# STM32F207 register map
File version: 1.2
CPU: CM3 r1p1, little endian, no MPU, no FPU, 4 interrupt priority bits
Registers are 32-bit, read-write, reset 0x0 unless marked. A register's access mark holds for its fields unless they carry their own. Offsets are from the block's base; [hi:lo] are bit positions; {n}, {i} and the like mark numbered series.

## DCMI — Digital camera interface
Base 0x50050000
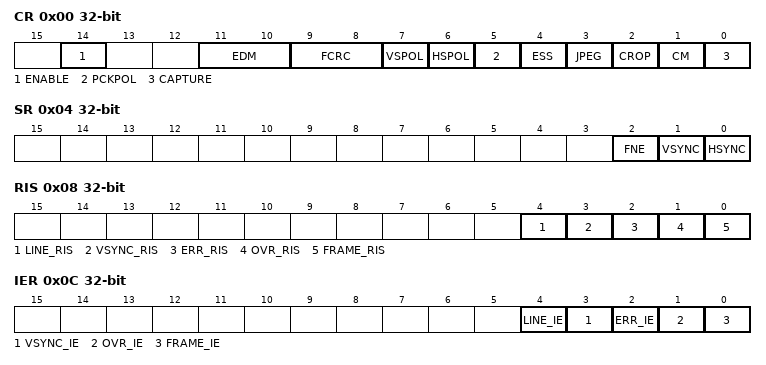
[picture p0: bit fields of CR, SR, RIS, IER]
0x00 CR — control register 1
  [14] ENABLE — DCMI enable
  [11:10] EDM — Extended data mode
  [9:8] FCRC — Frame capture rate control
  [7] VSPOL — Vertical synchronization polarity
  [6] HSPOL — Horizontal synchronization polarity
  [5] PCKPOL — Pixel clock polarity
  [4] ESS — Embedded synchronization select
  [3] JPEG — JPEG format
  [2] CROP — Crop feature
  [1] CM — Capture mode
  [0] CAPTURE — Capture enable
0x04 SR ro — status register
  [2] FNE — FIFO not empty
  [1] VSYNC
  [0] HSYNC
0x08 RIS ro — raw interrupt status register
  [4] LINE_RIS — Line raw interrupt status
  [3] VSYNC_RIS — VSYNC raw interrupt status
  [2] ERR_RIS — Synchronization error raw interrupt status
  [1] OVR_RIS — Overrun raw interrupt status
  [0] FRAME_RIS — Capture complete raw interrupt status
0x0C IER — interrupt enable register
  [4] LINE_IE — Line interrupt enable
  [3] VSYNC_IE — VSYNC interrupt enable
  [2] ERR_IE — Synchronization error interrupt enable
  [1] OVR_IE — Overrun interrupt enable
  [0] FRAME_IE — Capture complete interrupt enable
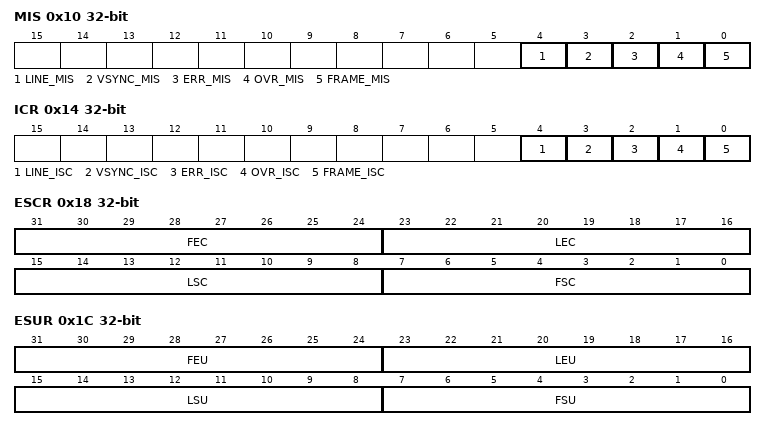
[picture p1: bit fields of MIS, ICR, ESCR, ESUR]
0x10 MIS ro — masked interrupt status register
  [4] LINE_MIS — Line masked interrupt status
  [3] VSYNC_MIS — VSYNC masked interrupt status
  [2] ERR_MIS — Synchronization error masked interrupt status
  [1] OVR_MIS — Overrun masked interrupt status
  [0] FRAME_MIS — Capture complete masked interrupt status
0x14 ICR wo — interrupt clear register
  [4] LINE_ISC — line interrupt status clear
  [3] VSYNC_ISC — Vertical synch interrupt status clear
  [2] ERR_ISC — Synchronization error interrupt status clear
  [1] OVR_ISC — Overrun interrupt status clear
  [0] FRAME_ISC — Capture complete interrupt status clear
0x18 ESCR — embedded synchronization code register
  [31:24] FEC — Frame end delimiter code
  [23:16] LEC — Line end delimiter code
  [15:8] LSC — Line start delimiter code
  [7:0] FSC — Frame start delimiter code
0x1C ESUR — embedded synchronization unmask register
  [31:24] FEU — Frame end delimiter unmask
  [23:16] LEU — Line end delimiter unmask
  [15:8] LSU — Line start delimiter unmask
  [7:0] FSU — Frame start delimiter unmask
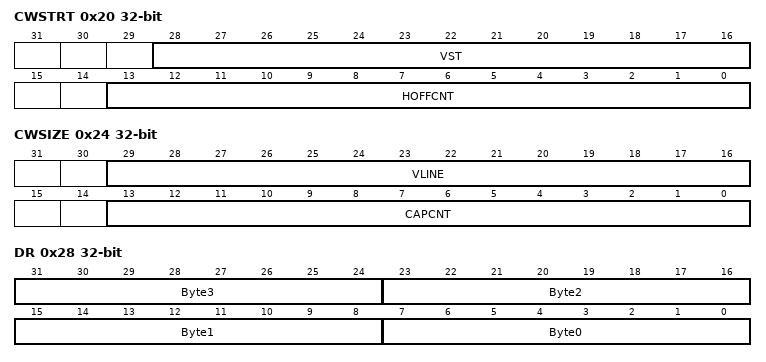
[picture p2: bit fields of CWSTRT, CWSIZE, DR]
0x20 CWSTRT — crop window start
  [28:16] VST — Vertical start line count
  [13:0] HOFFCNT — Horizontal offset count
0x24 CWSIZE — crop window size
  [29:16] VLINE — Vertical line count
  [13:0] CAPCNT — Capture count
0x28 DR ro — data register
  [8n+7:8n] Byte{n} (n=0..3) — Data byte {n}

## EXTI — External interrupt/event controller
Base 0x40013C00
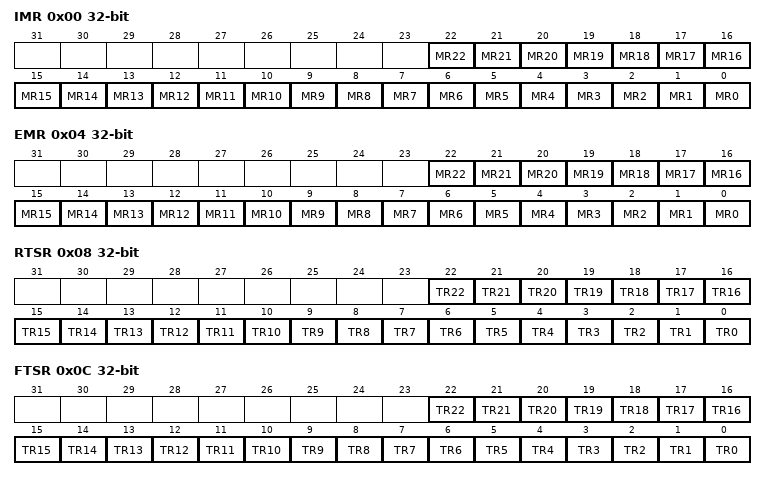
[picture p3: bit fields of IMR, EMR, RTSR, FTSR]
0x00 IMR — Interrupt mask register (EXTI_IMR)
  [n] MR{n} (n=0..22) — Interrupt Mask on line {n}
0x04 EMR — Event mask register (EXTI_EMR)
  [n] MR{n} (n=0..22) — Event Mask on line {n}
0x08 RTSR — Rising Trigger selection register (EXTI_RTSR)
  [n] TR{n} (n=0..22) — Rising trigger event configuration of line {n}
0x0C FTSR — Falling Trigger selection register (EXTI_FTSR)
  [n] TR{n} (n=0..22) — Falling trigger event configuration of line {n}
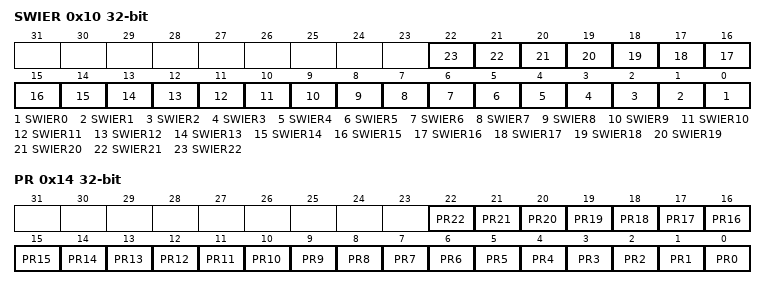
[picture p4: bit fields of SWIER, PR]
0x10 SWIER — Software interrupt event register (EXTI_SWIER)
  [n] SWIER{n} (n=0..22) — Software Interrupt on line {n}
0x14 PR — Pending register (EXTI_PR)
  [n] PR{n} (n=0..22) — Pending bit {n}

## Ethernet_MMC — Ethernet: MAC management counters
Base 0x40028100
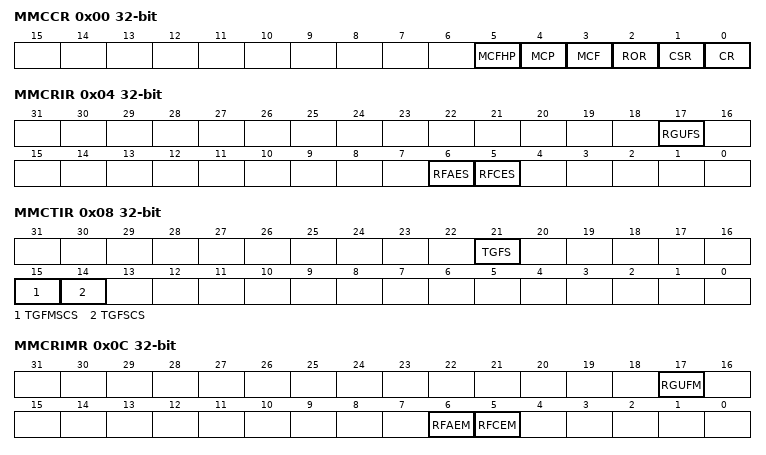
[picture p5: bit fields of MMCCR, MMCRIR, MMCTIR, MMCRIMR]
0x00 MMCCR — Ethernet MMC control register
  [5] MCFHP — MMC counter Full-Half preset
  [4] MCP — MMC counter preset
  [3] MCF — MMC counter freeze
  [2] ROR — Reset on read
  [1] CSR — Counter stop rollover
  [0] CR — Counter reset
0x04 MMCRIR — Ethernet MMC receive interrupt register
  [17] RGUFS — Received Good Unicast Frames Status
  [6] RFAES — Received frames alignment error status
  [5] RFCES — Received frames CRC error status
0x08 MMCTIR — Ethernet MMC transmit interrupt register
  [21] TGFS — Transmitted good frames status
  [15] TGFMSCS — Transmitted good frames more single collision status
  [14] TGFSCS — Transmitted good frames single collision status
0x0C MMCRIMR — Ethernet MMC receive interrupt mask register
  [17] RGUFM — Received good unicast frames mask
  [6] RFAEM — Received frames alignment error mask
  [5] RFCEM — Received frame CRC error mask
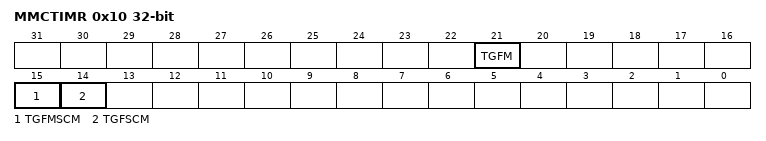
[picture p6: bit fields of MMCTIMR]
0x10 MMCTIMR — Ethernet MMC transmit interrupt mask register
  [21] TGFM — Transmitted good frames mask
  [15] TGFMSCM — Transmitted good frames more single collision mask
  [14] TGFSCM — Transmitted good frames single collision mask
0x4C MMCTGFSCCR ro — Ethernet MMC transmitted good frames after a single collision counter
  [31:0] TGFSCC — Transmitted good frames single collision counter
0x50 MMCTGFMSCCR ro — Ethernet MMC transmitted good frames after more than a single collision
  [31:0] TGFMSCC — Transmitted good frames more single collision counter
0x68 MMCTGFCR ro — Ethernet MMC transmitted good frames counter register
  [31:0] TGFC — Transmitted good frames counter
0x94 MMCRFCECR ro — Ethernet MMC received frames with CRC error counter register
  [31:0] RFCFC — Received frames CRC error counter
0x98 MMCRFAECR ro — Ethernet MMC received frames with alignment error counter register
  [31:0] RFAEC — Received frames alignment error counter
0xC4 MMCRGUFCR ro — MMC received good unicast frames counter register
  [31:0] RGUFC — Received good unicast frames counter
